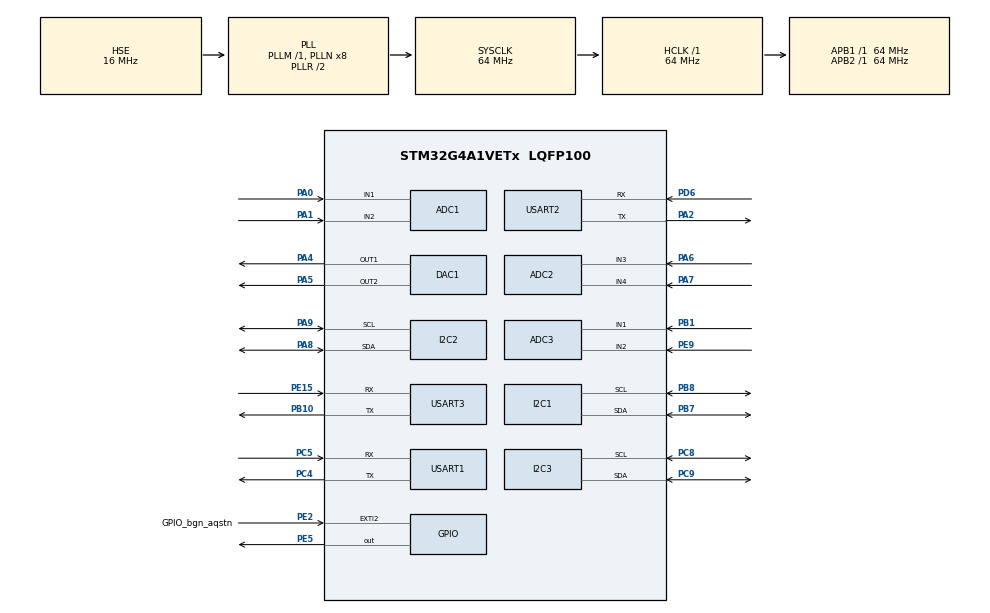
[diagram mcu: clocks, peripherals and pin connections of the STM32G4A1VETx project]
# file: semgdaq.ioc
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ADC1.Channel-0\#ChannelRegularConversion=ADC_CHANNEL_1
ADC1.Channel-1\#ChannelRegularConversion=ADC_CHANNEL_2
ADC1.ContinuousConvMode=DISABLE
ADC1.DMAContinuousRequests=ENABLE
ADC1.ExternalTrigConv=ADC_EXTERNALTRIG_T6_TRGO
ADC1.NbrOfConversion=2
ADC1.NbrOfConversionFlag=1
ADC1.OffsetNumber-0\#ChannelRegularConversion=ADC_OFFSET_NONE
ADC1.OffsetNumber-1\#ChannelRegularConversion=ADC_OFFSET_NONE
ADC1.Rank-0\#ChannelRegularConversion=1
ADC1.Rank-1\#ChannelRegularConversion=2
ADC1.SamplingTime-0\#ChannelRegularConversion=ADC_SAMPLETIME_92CYCLES_5
ADC1.SamplingTime-1\#ChannelRegularConversion=ADC_SAMPLETIME_92CYCLES_5
ADC1.master=1
ADC2.Channel-0\#ChannelRegularConversion=ADC_CHANNEL_3
ADC2.Channel-1\#ChannelRegularConversion=ADC_CHANNEL_4
ADC2.DMAContinuousRequests=ENABLE
ADC2.ExternalTrigConv=ADC_EXTERNALTRIG_T7_TRGO
ADC2.NbrOfConversion=2
ADC2.NbrOfConversionFlag=1
ADC2.OffsetNumber-0\#ChannelRegularConversion=ADC_OFFSET_NONE
ADC2.OffsetNumber-1\#ChannelRegularConversion=ADC_OFFSET_NONE
ADC2.Rank-0\#ChannelRegularConversion=1
ADC2.Rank-1\#ChannelRegularConversion=2
ADC2.SamplingTime-0\#ChannelRegularConversion=ADC_SAMPLETIME_92CYCLES_5
ADC2.SamplingTime-1\#ChannelRegularConversion=ADC_SAMPLETIME_92CYCLES_5
ADC3.Channel-0\#ChannelRegularConversion=ADC_CHANNEL_1
ADC3.Channel-1\#ChannelRegularConversion=ADC_CHANNEL_2
ADC3.DMAContinuousRequests=ENABLE
ADC3.ExternalTrigConv=ADC_EXTERNALTRIG_T20_TRGO
ADC3.NbrOfConversion=2
ADC3.NbrOfConversionFlag=1
ADC3.OffsetNumber-0\#ChannelRegularConversion=ADC_OFFSET_NONE
ADC3.OffsetNumber-1\#ChannelRegularConversion=ADC_OFFSET_NONE
ADC3.Rank-0\#ChannelRegularConversion=1
ADC3.Rank-1\#ChannelRegularConversion=2
ADC3.SamplingTime-0\#ChannelRegularConversion=ADC_SAMPLETIME_92CYCLES_5
ADC3.SamplingTime-1\#ChannelRegularConversion=ADC_SAMPLETIME_92CYCLES_5
ADC3.master=1
DAC1.DAC_Channel-DAC_OUT2=DAC_CHANNEL_2
DAC1.DAC_Trigger_OUT1-DAC_OUT1=DAC_TRIGGER_T6_TRGO
DAC1.DAC_Trigger_OUT2-DAC_OUT2=DAC_TRIGGER_T7_TRGO
Dma.ADC1.0.Direction=DMA_PERIPH_TO_MEMORY
Dma.ADC1.0.EventEnable=DISABLE
Dma.ADC1.0.Instance=DMA1_Channel1
Dma.ADC1.0.MemDataAlignment=DMA_MDATAALIGN_WORD
Dma.ADC1.0.MemInc=DMA_MINC_ENABLE
Dma.ADC1.0.Mode=DMA_CIRCULAR
Dma.ADC1.0.PeriphDataAlignment=DMA_PDATAALIGN_HALFWORD
Dma.ADC1.0.PeriphInc=DMA_PINC_DISABLE
Dma.ADC1.0.Polarity=HAL_DMAMUX_REQ_GEN_RISING
Dma.ADC1.0.Priority=DMA_PRIORITY_LOW
Dma.ADC1.0.RequestNumber=1
Dma.ADC1.0.SignalID=NONE
Dma.ADC1.0.SyncEnable=DISABLE
Dma.ADC1.0.SyncPolarity=HAL_DMAMUX_SYNC_NO_EVENT
Dma.ADC1.0.SyncRequestNumber=1
Dma.ADC1.0.SyncSignalID=NONE
Dma.ADC2.1.Direction=DMA_PERIPH_TO_MEMORY
Dma.ADC2.1.EventEnable=DISABLE
Dma.ADC2.1.Instance=DMA1_Channel6
Dma.ADC2.1.MemDataAlignment=DMA_MDATAALIGN_WORD
Dma.ADC2.1.MemInc=DMA_MINC_ENABLE
Dma.ADC2.1.Mode=DMA_CIRCULAR
Dma.ADC2.1.PeriphDataAlignment=DMA_PDATAALIGN_HALFWORD
Dma.ADC2.1.PeriphInc=DMA_PINC_DISABLE
Dma.ADC2.1.Polarity=HAL_DMAMUX_REQ_GEN_RISING
Dma.ADC2.1.Priority=DMA_PRIORITY_LOW
Dma.ADC2.1.RequestNumber=1
Dma.ADC2.1.SignalID=NONE
Dma.ADC2.1.SyncEnable=DISABLE
Dma.ADC2.1.SyncPolarity=HAL_DMAMUX_SYNC_NO_EVENT
Dma.ADC2.1.SyncRequestNumber=1
Dma.ADC2.1.SyncSignalID=NONE
Dma.ADC3.2.Direction=DMA_PERIPH_TO_MEMORY
Dma.ADC3.2.EventEnable=DISABLE
Dma.ADC3.2.Instance=DMA2_Channel1
Dma.ADC3.2.MemDataAlignment=DMA_MDATAALIGN_WORD
Dma.ADC3.2.MemInc=DMA_MINC_ENABLE
Dma.ADC3.2.Mode=DMA_CIRCULAR
Dma.ADC3.2.PeriphDataAlignment=DMA_PDATAALIGN_HALFWORD
Dma.ADC3.2.PeriphInc=DMA_PINC_DISABLE
Dma.ADC3.2.Polarity=HAL_DMAMUX_REQ_GEN_RISING
Dma.ADC3.2.Priority=DMA_PRIORITY_LOW
Dma.ADC3.2.RequestNumber=1
Dma.ADC3.2.SignalID=NONE
Dma.ADC3.2.SyncEnable=DISABLE
Dma.ADC3.2.SyncPolarity=HAL_DMAMUX_SYNC_NO_EVENT
Dma.ADC3.2.SyncRequestNumber=1
Dma.ADC3.2.SyncSignalID=NONE
Dma.DAC1_CH1.3.Direction=DMA_MEMORY_TO_PERIPH
Dma.DAC1_CH1.3.EventEnable=DISABLE
Dma.DAC1_CH1.3.Instance=DMA1_Channel3
Dma.DAC1_CH1.3.MemDataAlignment=DMA_MDATAALIGN_WORD
Dma.DAC1_CH1.3.MemInc=DMA_MINC_ENABLE
Dma.DAC1_CH1.3.Mode=DMA_CIRCULAR
Dma.DAC1_CH1.3.PeriphDataAlignment=DMA_PDATAALIGN_WORD
Dma.DAC1_CH1.3.PeriphInc=DMA_PINC_DISABLE
Dma.DAC1_CH1.3.Polarity=HAL_DMAMUX_REQ_GEN_RISING
Dma.DAC1_CH1.3.Priority=DMA_PRIORITY_LOW
Dma.DAC1_CH1.3.RequestNumber=1
Dma.DAC1_CH1.3.SignalID=NONE
Dma.DAC1_CH1.3.SyncEnable=DISABLE
Dma.DAC1_CH1.3.SyncPolarity=HAL_DMAMUX_SYNC_NO_EVENT
Dma.DAC1_CH1.3.SyncRequestNumber=1
Dma.DAC1_CH1.3.SyncSignalID=NONE
Dma.DAC1_CH2.4.Direction=DMA_MEMORY_TO_PERIPH
Dma.DAC1_CH2.4.EventEnable=DISABLE
Dma.DAC1_CH2.4.Instance=DMA2_Channel6
Dma.DAC1_CH2.4.MemDataAlignment=DMA_MDATAALIGN_WORD
Dma.DAC1_CH2.4.MemInc=DMA_MINC_ENABLE
Dma.DAC1_CH2.4.Mode=DMA_CIRCULAR
Dma.DAC1_CH2.4.PeriphDataAlignment=DMA_PDATAALIGN_WORD
Dma.DAC1_CH2.4.PeriphInc=DMA_PINC_DISABLE
Dma.DAC1_CH2.4.Polarity=HAL_DMAMUX_REQ_GEN_RISING
Dma.DAC1_CH2.4.Priority=DMA_PRIORITY_LOW
Dma.DAC1_CH2.4.RequestNumber=1
Dma.DAC1_CH2.4.SignalID=NONE
Dma.DAC1_CH2.4.SyncEnable=DISABLE
Dma.DAC1_CH2.4.SyncPolarity=HAL_DMAMUX_SYNC_NO_EVENT
Dma.DAC1_CH2.4.SyncRequestNumber=1
Dma.DAC1_CH2.4.SyncSignalID=NONE
Dma.I2C1_TX.8.Direction=DMA_MEMORY_TO_PERIPH
Dma.I2C1_TX.8.EventEnable=DISABLE
Dma.I2C1_TX.8.Instance=DMA1_Channel4
Dma.I2C1_TX.8.MemDataAlignment=DMA_MDATAALIGN_WORD
Dma.I2C1_TX.8.MemInc=DMA_MINC_ENABLE
Dma.I2C1_TX.8.Mode=DMA_CIRCULAR
Dma.I2C1_TX.8.PeriphDataAlignment=DMA_PDATAALIGN_WORD
Dma.I2C1_TX.8.PeriphInc=DMA_PINC_DISABLE
Dma.I2C1_TX.8.Polarity=HAL_DMAMUX_REQ_GEN_RISING
Dma.I2C1_TX.8.Priority=DMA_PRIORITY_LOW
Dma.I2C1_TX.8.RequestNumber=1
Dma.I2C1_TX.8.SignalID=NONE
Dma.I2C1_TX.8.SyncEnable=DISABLE
Dma.I2C1_TX.8.SyncPolarity=HAL_DMAMUX_SYNC_NO_EVENT
Dma.I2C1_TX.8.SyncRequestNumber=1
Dma.I2C1_TX.8.SyncSignalID=NONE
Dma.I2C2_TX.9.Direction=DMA_MEMORY_TO_PERIPH
Dma.I2C2_TX.9.EventEnable=DISABLE
Dma.I2C2_TX.9.Instance=DMA2_Channel5
Dma.I2C2_TX.9.MemDataAlignment=DMA_MDATAALIGN_WORD
Dma.I2C2_TX.9.MemInc=DMA_MINC_ENABLE
Dma.I2C2_TX.9.Mode=DMA_CIRCULAR
Dma.I2C2_TX.9.PeriphDataAlignment=DMA_PDATAALIGN_WORD
Dma.I2C2_TX.9.PeriphInc=DMA_PINC_DISABLE
Dma.I2C2_TX.9.Polarity=HAL_DMAMUX_REQ_GEN_RISING
Dma.I2C2_TX.9.Priority=DMA_PRIORITY_LOW
Dma.I2C2_TX.9.RequestNumber=1
Dma.I2C2_TX.9.SignalID=NONE
Dma.I2C2_TX.9.SyncEnable=DISABLE
Dma.I2C2_TX.9.SyncPolarity=HAL_DMAMUX_SYNC_NO_EVENT
Dma.I2C2_TX.9.SyncRequestNumber=1
Dma.I2C2_TX.9.SyncSignalID=NONE
Dma.I2C3_TX.10.Direction=DMA_MEMORY_TO_PERIPH
Dma.I2C3_TX.10.EventEnable=DISABLE
Dma.I2C3_TX.10.Instance=DMA2_Channel7
Dma.I2C3_TX.10.MemDataAlignment=DMA_MDATAALIGN_WORD
Dma.I2C3_TX.10.MemInc=DMA_MINC_ENABLE
Dma.I2C3_TX.10.Mode=DMA_CIRCULAR
Dma.I2C3_TX.10.PeriphDataAlignment=DMA_PDATAALIGN_WORD
Dma.I2C3_TX.10.PeriphInc=DMA_PINC_DISABLE
Dma.I2C3_TX.10.Polarity=HAL_DMAMUX_REQ_GEN_RISING
Dma.I2C3_TX.10.Priority=DMA_PRIORITY_LOW
Dma.I2C3_TX.10.RequestNumber=1
Dma.I2C3_TX.10.SignalID=NONE
Dma.I2C3_TX.10.SyncEnable=DISABLE
Dma.I2C3_TX.10.SyncPolarity=HAL_DMAMUX_SYNC_NO_EVENT
Dma.I2C3_TX.10.SyncRequestNumber=1
Dma.I2C3_TX.10.SyncSignalID=NONE
Dma.Request0=ADC1
Dma.Request1=ADC2
Dma.Request10=I2C3_TX
Dma.Request2=ADC3
Dma.Request3=DAC1_CH1
Dma.Request4=DAC1_CH2
Dma.Request5=USART1_TX
Dma.Request6=USART3_TX
Dma.Request7=USART2_TX
Dma.Request8=I2C1_TX
Dma.Request9=I2C2_TX
Dma.USART1_TX.5.Direction=DMA_MEMORY_TO_PERIPH
Dma.USART1_TX.5.EventEnable=DISABLE
Dma.USART1_TX.5.Instance=DMA1_Channel2
Dma.USART1_TX.5.MemDataAlignment=DMA_MDATAALIGN_WORD
Dma.USART1_TX.5.MemInc=DMA_MINC_ENABLE
Dma.USART1_TX.5.Mode=DMA_CIRCULAR
Dma.USART1_TX.5.PeriphDataAlignment=DMA_PDATAALIGN_WORD
Dma.USART1_TX.5.PeriphInc=DMA_PINC_DISABLE
Dma.USART1_TX.5.Polarity=HAL_DMAMUX_REQ_GEN_RISING
Dma.USART1_TX.5.Priority=DMA_PRIORITY_LOW
Dma.USART1_TX.5.RequestNumber=1
Dma.USART1_TX.5.SignalID=NONE
Dma.USART1_TX.5.SyncEnable=DISABLE
Dma.USART1_TX.5.SyncPolarity=HAL_DMAMUX_SYNC_NO_EVENT
Dma.USART1_TX.5.SyncRequestNumber=1
Dma.USART1_TX.5.SyncSignalID=NONE
Dma.USART2_TX.7.Direction=DMA_MEMORY_TO_PERIPH
Dma.USART2_TX.7.EventEnable=DISABLE
Dma.USART2_TX.7.Instance=DMA1_Channel5
Dma.USART2_TX.7.MemDataAlignment=DMA_MDATAALIGN_WORD
Dma.USART2_TX.7.MemInc=DMA_MINC_ENABLE
Dma.USART2_TX.7.Mode=DMA_CIRCULAR
Dma.USART2_TX.7.PeriphDataAlignment=DMA_PDATAALIGN_WORD
Dma.USART2_TX.7.PeriphInc=DMA_PINC_DISABLE
Dma.USART2_TX.7.Polarity=HAL_DMAMUX_REQ_GEN_RISING
Dma.USART2_TX.7.Priority=DMA_PRIORITY_LOW
Dma.USART2_TX.7.RequestNumber=1
Dma.USART2_TX.7.SignalID=NONE
Dma.USART2_TX.7.SyncEnable=DISABLE
Dma.USART2_TX.7.SyncPolarity=HAL_DMAMUX_SYNC_NO_EVENT
Dma.USART2_TX.7.SyncRequestNumber=1
Dma.USART2_TX.7.SyncSignalID=NONE
Dma.USART3_TX.6.Direction=DMA_MEMORY_TO_PERIPH
Dma.USART3_TX.6.EventEnable=DISABLE
Dma.USART3_TX.6.Instance=DMA2_Channel4
Dma.USART3_TX.6.MemDataAlignment=DMA_MDATAALIGN_WORD
Dma.USART3_TX.6.MemInc=DMA_MINC_ENABLE
Dma.USART3_TX.6.Mode=DMA_CIRCULAR
Dma.USART3_TX.6.PeriphDataAlignment=DMA_PDATAALIGN_WORD
Dma.USART3_TX.6.PeriphInc=DMA_PINC_DISABLE
Dma.USART3_TX.6.Polarity=HAL_DMAMUX_REQ_GEN_RISING
Dma.USART3_TX.6.Priority=DMA_PRIORITY_LOW
Dma.USART3_TX.6.RequestNumber=1
Dma.USART3_TX.6.SignalID=NONE
Dma.USART3_TX.6.SyncEnable=DISABLE
Dma.USART3_TX.6.SyncPolarity=HAL_DMAMUX_SYNC_NO_EVENT
Dma.USART3_TX.6.SyncRequestNumber=1
Dma.USART3_TX.6.SyncSignalID=NONE
I2C1.Timing=0x10707DBC
I2C2.Timing=0x10707DBC
I2C3.Timing=0x10707DBC
Mcu.Family=STM32G4
Mcu.Name=STM32G4A1VETx
Mcu.Package=LQFP100
NVIC.DMA1_Channel1_IRQn=true\:0\:0\:false\:false\:true\:false\:true\:true
NVIC.DMA1_Channel2_IRQn=true\:0\:0\:false\:false\:true\:false\:true\:true
NVIC.DMA1_Channel3_IRQn=true\:0\:0\:false\:false\:true\:false\:true\:true
NVIC.DMA1_Channel4_IRQn=true\:0\:0\:false\:false\:true\:false\:true\:true
NVIC.DMA1_Channel5_IRQn=true\:0\:0\:false\:false\:true\:false\:true\:true
NVIC.DMA1_Channel6_IRQn=true\:0\:0\:false\:false\:true\:false\:true\:true
NVIC.DMA2_Channel1_IRQn=true\:0\:0\:false\:false\:true\:false\:true\:true
NVIC.DMA2_Channel4_IRQn=true\:0\:0\:false\:false\:true\:false\:true\:true
NVIC.DMA2_Channel5_IRQn=true\:0\:0\:false\:false\:true\:false\:true\:true
NVIC.DMA2_Channel6_IRQn=true\:0\:0\:false\:false\:true\:false\:true\:true
NVIC.DMA2_Channel7_IRQn=true\:0\:0\:false\:false\:true\:false\:true\:true
NVIC.PriorityGroup=NVIC_PRIORITYGROUP_4
PA0.Mode=IN1-Single-Ended
PA0.Signal=ADC1_IN1
PA1.Mode=IN2-Single-Ended
PA1.Signal=ADC1_IN2
PA13.Mode=JTAG_4_pins
PA13.Signal=SYS_JTMS-SWDIO
PA14.Mode=JTAG_4_pins
PA14.Signal=SYS_JTCK-SWCLK
PA15.Mode=JTAG_4_pins
PA15.Signal=SYS_JTDI
PA2.Mode=Asynchronous
PA2.Signal=USART2_TX
PA4.Signal=COMP_DAC11_group
PA5.Signal=COMP_DAC12_group
PA6.Mode=IN3-Single-Ended
PA6.Signal=ADC2_IN3
PA7.Mode=IN4-Single-Ended
PA7.Signal=ADC2_IN4
PA8.Mode=I2C
PA8.Signal=I2C2_SDA
PA9.Mode=I2C
PA9.Signal=I2C2_SCL
PB1.Mode=IN1-Single-Ended
PB1.Signal=ADC3_IN1
PB10.Mode=Asynchronous
PB10.Signal=USART3_TX
PB3.Mode=JTAG_4_pins
PB3.Signal=SYS_JTDO-SWO
PB7.Mode=I2C
PB7.Signal=I2C1_SDA
PB8-BOOT0.Mode=I2C
PB8-BOOT0.Signal=I2C1_SCL
PC4.Mode=Asynchronous
PC4.Signal=USART1_TX
PC5.Mode=Asynchronous
PC5.Signal=USART1_RX
PC8.Mode=I2C
PC8.Signal=I2C3_SCL
PC9.Mode=I2C
PC9.Signal=I2C3_SDA
PD6.Mode=Asynchronous
PD6.Signal=USART2_RX
PE15.Mode=Asynchronous
PE15.Signal=USART3_RX
PE2.GPIO_Label=GPIO_bgn_aqstn
PE2.GPIO_ModeDefaultEXTI=GPIO_MODE_IT_RISING
PE2.GPIO_PuPd=GPIO_PULLDOWN
PE2.Signal=GPXTI2
PE5.Signal=GPIO_Output
PE9.Mode=IN2-Single-Ended
PE9.Signal=ADC3_IN2
PF0-OSC_IN.Mode=HSE-External-Oscillator
PF0-OSC_IN.Signal=RCC_OSC_IN
PF1-OSC_OUT.Mode=HSE-External-Oscillator
PF1-OSC_OUT.Signal=RCC_OSC_OUT
ProjectManager.HeapSize=0x200
ProjectManager.StackSize=0x400
ProjectManager.TargetToolchain=STM32CubeIDE
RCC.ADC12Freq_Value=64000000
RCC.ADC345Freq_Value=64000000
RCC.AHBFreq_Value=64000000
RCC.APB1Freq_Value=64000000
RCC.APB1TimFreq_Value=64000000
RCC.APB2Freq_Value=64000000
RCC.APB2TimFreq_Value=64000000
RCC.CortexFreq_Value=64000000
RCC.EXTERNAL_CLOCK_VALUE=12288000
RCC.HCLKFreq_Value=64000000
RCC.HSE_VALUE=16000000
RCC.HSI48_VALUE=48000000
RCC.HSI_VALUE=16000000
RCC.LSE_VALUE=32768
RCC.PLLSourceVirtual=RCC_PLLSOURCE_HSE
RCC.SYSCLKFreq_VALUE=64000000
RCC.SYSCLKSource=RCC_SYSCLKSOURCE_PLLCLK
RCC.USBFreq_Value=48000000
RCC.VCOOutputFreq_Value=128000000
SH.COMP_DAC11_group.0=DAC1_OUT1,DAC_OUT1
SH.COMP_DAC12_group.0=DAC1_OUT2,DAC_OUT2
TIM20.PeriodNoDither=8-1
TIM20.Prescaler=8-1
TIM20.TIM_MasterOutputTrigger=TIM_TRGO_UPDATE
TIM6.PeriodNoDither=8-1
TIM6.Prescaler=8-1
TIM6.TIM_MasterOutputTrigger=TIM_TRGO_UPDATE
TIM7.PeriodNoDither=8-1
TIM7.Prescaler=8-1
TIM7.TIM_MasterOutputTrigger=TIM_TRGO_UPDATE
USART1.VirtualMode-Asynchronous=VM_ASYNC
USART2.VirtualMode-Asynchronous=VM_ASYNC
USART3.VirtualMode-Asynchronous=VM_ASYNC
VP_FMAC_VS_FMAC.Mode=FMAC_Activate
VP_SYS_VS_DBSignals.Mode=DisableDeadBatterySignals
VP_TIM20_VS_ClockSourceITR.Mode=TriggerSource_ITR0
VP_TIM6_VS_ClockSourceINT.Mode=Enable_Timer
VP_TIM7_VS_ClockSourceINT.Mode=Enable_Timer
board=custom

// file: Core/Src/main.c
/* USER CODE BEGIN Header */
/**
  ******************************************************************************
  * @file           : main.c
  * @brief          : Main program body
  ******************************************************************************
  * @attention
  *
  * Copyright (c) 2024 STMicroelectronics.
  * All rights reserved.
  *
  * This software is licensed under terms that can be found in the LICENSE file
  * in the root directory of this software component.
  * If no LICENSE file comes with this software, it is provided AS-IS.
  *
  ******************************************************************************
  */
/* USER CODE END Header */
#include "main.h"

/* USER CODE BEGIN Includes */
#include <_ADCn_INx_DAC1_Cond.h>
/* USER CODE END Includes */

/* USER CODE BEGIN PD */
#define NOOFITERATIONS_BL 20
/* USER CODE END PD */

ADC_HandleTypeDef hadc1;
ADC_HandleTypeDef hadc2;
ADC_HandleTypeDef hadc3;
DMA_HandleTypeDef hdma_adc1;
DMA_HandleTypeDef hdma_adc2;
DMA_HandleTypeDef hdma_adc3;

DAC_HandleTypeDef hdac1;
DMA_HandleTypeDef hdma_dac1_ch1;
DMA_HandleTypeDef hdma_dac1_ch2;

FMAC_HandleTypeDef hfmac;

I2C_HandleTypeDef hi2c1;
I2C_HandleTypeDef hi2c2;
I2C_HandleTypeDef hi2c3;
DMA_HandleTypeDef hdma_i2c1_tx;
DMA_HandleTypeDef hdma_i2c2_tx;
DMA_HandleTypeDef hdma_i2c3_tx;

TIM_HandleTypeDef htim6;
TIM_HandleTypeDef htim7;
TIM_HandleTypeDef htim20;

UART_HandleTypeDef huart1;
UART_HandleTypeDef huart2;
UART_HandleTypeDef huart3;
DMA_HandleTypeDef hdma_usart1_tx;
DMA_HandleTypeDef hdma_usart2_tx;
DMA_HandleTypeDef hdma_usart3_tx;

/* USER CODE BEGIN PV */
ADC1_DMA_sort*ADC1_DMA_sort_ptr; // Declaring a pointer to the sorting structure at runtime
ADC2_DMA_sort*ADC2_DMA_sort_ptr;
ADC3_DMA_sort*ADC3_DMA_sort_ptr;

ADC1_IN1_MA MovingAverage_ADC1_IN1; // Declaring an instance of the moving average structure
ADC1_IN2_MA MovingAverage_ADC1_IN2;
ADC2_IN3_MA MovingAverage_ADC2_IN3;
ADC2_IN4_MA MovingAverage_ADC2_IN4;
ADC3_IN1_MA MovingAverage_ADC3_IN1;
ADC3_IN2_MA MovingAverage_ADC3_IN2;

ADC1_IN1_MA OffsetCalc_ADC1_IN1; // Declaring an instance of the Offset calculation
ADC1_IN2_MA OffsetCalc_ADC1_IN2;
ADC2_IN3_MA OffsetCalc_ADC2_IN3;
ADC2_IN4_MA OffsetCalc_ADC2_IN4;
ADC3_IN1_MA OffsetCalc_ADC3_IN1;
ADC3_IN2_MA OffsetCalc_ADC3_IN2;

ADC1_IN1_MA SD_BL_ADC1_IN1; // Declaring an instance of standard deviation calculation
ADC1_IN2_MA SD_BL_ADC1_IN2;
ADC2_IN3_MA SD_BL_ADC2_IN3;
ADC2_IN4_MA SD_BL_ADC2_IN4;
ADC3_IN1_MA SD_BL_ADC3_IN1;
ADC3_IN2_MA SD_BL_ADC3_IN2;

ADC1_IN1_MA TKEO_ADC1_IN1; // Declaring an instance of TKEO windowing
ADC1_IN2_MA TKEO_ADC1_IN2;
ADC2_IN3_MA TKEO_ADC2_IN3;
ADC2_IN4_MA TKEO_ADC2_IN4;
ADC3_IN1_MA TKEO_ADC3_IN1;
ADC3_IN2_MA TKEO_ADC3_IN2;

ADC1_IN1_MA SSC_ADC1_IN1; // Declaring an instance of slope sign change feature
ADC1_IN2_MA SSC_ADC1_IN2;
ADC2_IN3_MA SSC_ADC2_IN3;
ADC2_IN4_MA SSC_ADC2_IN4;
ADC3_IN1_MA SSC_ADC3_IN1;
ADC3_IN2_MA SSC_ADC3_IN2;

ADC1_IN1_MA STFT_ADC1_IN1; // Declaring an instance of short time Fourier transform
ADC1_IN2_MA STFT_ADC1_IN2;
ADC2_IN3_MA STFT_ADC2_IN3;
ADC2_IN4_MA STFT_ADC2_IN4;
ADC3_IN1_MA STFT_ADC3_IN1;
ADC3_IN2_MA STFT_ADC3_IN2;

ADC1_IN1_MA DAC1_ADC1_IN1; // Declaring an instance for DAC monitoring
ADC1_IN2_MA DAC1_ADC1_IN2;
ADC2_IN3_MA DAC1_ADC2_IN3;
ADC2_IN4_MA DAC1_ADC2_IN4;
ADC3_IN1_MA DAC1_ADC3_IN1;
ADC3_IN2_MA DAC1_ADC3_IN2;

ADC1_IN1_STFT_par STFT_par_ADC1_IN1; // Declaring an instance of short time Fourier transform parameters
ADC1_IN2_STFT_par STFT_par_ADC1_IN2;
ADC2_IN3_STFT_par STFT_par_ADC2_IN3;
ADC2_IN4_STFT_par STFT_par_ADC2_IN4;
ADC3_IN1_STFT_par STFT_par_ADC3_IN1;
ADC3_IN2_STFT_par STFT_par_ADC3_IN2;

HAL_StatusTypeDef ADC_status;

float32_t Offset_1 = 0.0f; // Variable to store the calculated offset
float32_t Offset_2 = 0.0f;
float32_t Offset_3 = 0.0f;
float32_t Offset_4 = 0.0f;
float32_t Offset_5 = 0.0f;
float32_t Offset_6 = 0.0f;

uint8_t Offset_1_Calculated = 0; // Initialize the offset calculation flag to zero
uint8_t Offset_2_Calculated = 0;
uint8_t Offset_3_Calculated = 0;
uint8_t Offset_4_Calculated = 0;
uint8_t Offset_5_Calculated = 0;
uint8_t Offset_6_Calculated = 0;

float32_t SD_BL_1 = 0.0f;
float32_t SD_BL_2 = 0.0f;
float32_t SD_BL_3 = 0.0f;
float32_t SD_BL_4 = 0.0f;
float32_t SD_BL_5 = 0.0f;
float32_t SD_BL_6 = 0.0f;

uint8_t TKEO_1 = 0;
uint8_t TKEO_2 = 0;
uint8_t TKEO_3 = 0;
uint8_t TKEO_4 = 0;
uint8_t TKEO_5 = 0;
uint8_t TKEO_6 = 0;

float32_t SSC_1 = 0.0f;
float32_t SSC_2 = 0.0f;
float32_t SSC_3 = 0.0f;
float32_t SSC_4 = 0.0f;
float32_t SSC_5 = 0.0f;
float32_t SSC_6 = 0.0f;

float32_t* AR_1;
float32_t* AR_2;
float32_t* AR_3;
float32_t* AR_4;
float32_t* AR_5;
float32_t* AR_6;

float32_t* STFT_1;
float32_t* STFT_2;
float32_t* STFT_3;
float32_t* STFT_4;
float32_t* STFT_5;
float32_t* STFT_6;

volatile uint8_t Buffer_ADC1_Ready = 0;
volatile uint8_t Buffer_ADC2_Ready = 0;
volatile uint8_t Buffer_ADC3_Ready = 0;
/* USER CODE END PV */

void SystemClock_Config(void);
static void MX_GPIO_Init(void);
static void MX_DMA_Init(void);
static void MX_ADC1_Init(void);
static void MX_ADC2_Init(void);
static void MX_ADC3_Init(void);
static void MX_FMAC_Init(void);
static void MX_TIM6_Init(void);
static void MX_TIM7_Init(void);
static void MX_TIM20_Init(void);
static void MX_DAC1_Init(void);
static void MX_USART1_UART_Init(void);
static void MX_USART3_UART_Init(void);
static void MX_USART2_UART_Init(void);
static void MX_I2C1_Init(void);
static void MX_I2C2_Init(void);
static void MX_I2C3_Init(void);
/* USER CODE BEGIN PFP */
void EXT12_IRQHandler(void);
void HAL_GPIO_EXTI_Callback(uint16_t GPIO_Pin);
void                    HAL_ADC_ConvHalfCpltCallback(ADC_HandleTypeDef *hadc);
void                    HAL_ADC_ConvCpltCallback(ADC_HandleTypeDef *hadc);
void Error_Handler(void);
/* USER CODE END PFP */

int main(void)
{

  /* MCU Configuration--------------------------------------------------------*/

  /* Reset of all peripherals, Initializes the Flash interface and the Systick. */
  HAL_Init();

  /* USER CODE BEGIN Init */
  init_ADC1_IN1_struct(); // Pointer to the source buffer is initialized at runtime
  init_ADC1_IN1_FO_biquad_filter();  // Initializes the filter coefficients and variables
  MA_ADC1_IN1_Init(&MovingAverage_ADC1_IN1); // Initializes all the output and moving average buffers to zero and the index to zero

  init_ADC1_IN2_struct();
  init_ADC1_IN2_FO_biquad_filter();
  MA_ADC1_IN2_Init(&MovingAverage_ADC1_IN2);

  init_ADC2_IN3_struct();
  init_ADC2_IN3_FO_biquad_filter();
  MA_ADC2_IN3_Init(&MovingAverage_ADC2_IN3);

  init_ADC2_IN4_struct();
  init_ADC2_IN4_FO_biquad_filter();
  MA_ADC2_IN4_Init(&MovingAverage_ADC2_IN4);

  init_ADC3_IN1_struct();
  init_ADC3_IN1_FO_biquad_filter();
  MA_ADC3_IN1_Init(&MovingAverage_ADC3_IN1);

  init_ADC3_IN2_struct();
  init_ADC3_IN2_FO_biquad_filter();
  MA_ADC3_IN2_Init(&MovingAverage_ADC3_IN2);
  /* USER CODE END Init */

  /* Configure the system clock */
  SystemClock_Config();

  /* Initialize all configured peripherals */
  MX_GPIO_Init();
  MX_DMA_Init();
  MX_ADC1_Init();
  MX_ADC2_Init();
  MX_ADC3_Init();
  MX_FMAC_Init();
  MX_TIM6_Init();
  MX_TIM7_Init();
  MX_TIM20_Init();
  MX_DAC1_Init();
  MX_USART1_UART_Init();
  MX_USART3_UART_Init();
  MX_USART2_UART_Init();
  MX_I2C1_Init();
  MX_I2C2_Init();
  MX_I2C3_Init();
  /* USER CODE BEGIN 2 */
  // Enable the EXTI line 2 interrupt
  HAL_NVIC_SetPriority(EXTI2_IRQn, 2, 0);  // Set priority
  HAL_NVIC_EnableIRQ(EXTI2_IRQn); // Enable the interrupt in NVIC (Interrupt is triggered by pressing the push button)

  EXT12_IRQHandler(); // When the push button is pressed - starts all ADCs with DMA, starts the sorting algorithm for each ADC, calculates the offset from the baseline and the standard deviation from the baseline data (for all channels). Finally, it toggles the status LED to indicate that acquisition has started
  /* USER CODE END 2 */

  /* Infinite loop */
  /* USER CODE BEGIN WHILE */
  while (1)
  {
	if (Buffer_ADC1_Ready == 1) // Checks if the flag for the channel buffer fills is set for ADC1
	{
	  /* DSP SECTION */
	  update_ADC1_IN1_FO_biquad_filter();  // Filters channel 1 data
	  MA_ADC1_IN1_Update(&MovingAverage_ADC1_IN1); // Performs the moving average
	  for (uint32_t y = 0; y < ADC_DMA_SIXTEENTHBUFFERSIZE; y++)
	  {
		  MovingAverage_ADC1_IN1.MA_ADC1_IN1_OutBfr[y]  -= Offset_1; // Subtracts the stored offset
	  }
      #ifdef MONITOR_CHANNEL_1_LEFT
	  ADC1_IN1_DAC_Update(&DAC1_ADC1_IN1); // For monitoring the channel on an oscilloscope through the DAC
      #endif

	  /* FEATURE EXCTRACTION SECTION */
      TKEO_1 = ADC1_IN1_TKEO(&TKEO_ADC1_IN1, SD_BL_1); // Performs the windowing through the TKEO operator and returns binary data to indicate presence or absence of muscle activation

      if(TKEO_1 == 1) // Only runs when there is muscle activation.
      {
      /* Slope sign change */
      SSC_1 = ADC1_IN1_SSC(&SSC_ADC1_IN1, 0.5 * Offset_1); // Calculates slope sign changes for active segments
      /*Computes the autocorrelation values and the autoregression coefficients and returns the latter*/
      ADC1_IN1_autocorr_calc();
      AR_1 = ADC1_IN1_autoreg_coeffs();
      /* Computes the Short Time Fourier Transform from the moving average buffer */
      STFT_1 = ADC1_IN1_STFT_Update(&STFT_par_ADC1_IN1, &STFT_ADC1_IN1);
      }

	  update_ADC1_IN2_FO_biquad_filter();
	  MA_ADC1_IN2_Update(&MovingAverage_ADC1_IN2);
	  for (uint32_t z = 0; z < ADC_DMA_SIXTEENTHBUFFERSIZE; z++)
	  {
		  MovingAverage_ADC1_IN2.MA_ADC1_IN2_OutBfr[z]  -= Offset_2;
	  }
      #ifdef MONITOR_CHANNEL_4_RIGHT
	  ADC1_IN2_DAC_Update(&DAC1_ADC1_IN2);
      #endif

	  TKEO_2 = ADC1_IN2_TKEO(&TKEO_ADC1_IN2, SD_BL_2);

	  if(TKEO_2 == 1)
	  {
	  SSC_2 = ADC1_IN2_SSC(&SSC_ADC1_IN2, 0.5 * Offset_2);
	  ADC1_IN2_autocorr_calc();
	  AR_2 = ADC1_IN2_autoreg_coeffs();
	  STFT_2 = ADC1_IN2_STFT_Update(&STFT_par_ADC1_IN2, &STFT_ADC1_IN2);
	  }

	  Buffer_ADC1_Ready = 0; // After processing is done the flag is cleared

	}

	if (Buffer_ADC2_Ready == 1)
	{
	  update_ADC2_IN3_FO_biquad_filter();
	  MA_ADC2_IN3_Update(&MovingAverage_ADC2_IN3);
	  for (uint32_t g = 0; g <ADC_DMA_SIXTEENTHBUFFERSIZE; g++)
	  {
		  MovingAverage_ADC2_IN3.MA_ADC2_IN3_OutBfr[g]  -= Offset_3;
	  }

      #ifdef MONITOR_CHANNEL_2_LEFT
	  ADC2_IN3_DAC_Update(&DAC1_ADC2_IN3);
      #endif

	  TKEO_3 = ADC2_IN3_TKEO(&TKEO_ADC2_IN3, SD_BL_3);

	  if(TKEO_3 == 1)
	  {
	  SSC_3 = ADC2_IN3_SSC(&SSC_ADC2_IN3, 0.5 * Offset_3);
	  ADC2_IN3_autocorr_calc();
	  AR_3 = ADC2_IN3_autoreg_coeffs();
	  STFT_3 = ADC2_IN3_STFT_Update(&STFT_par_ADC2_IN3, &STFT_ADC2_IN3);
	  }

	  update_ADC2_IN4_FO_biquad_filter();
	  MA_ADC2_IN4_Update(&MovingAverage_ADC2_IN4);
	  for (uint32_t e = 0; e < ADC_DMA_SIXTEENTHBUFFERSIZE; e++)
	  {
		  MovingAverage_ADC2_IN4.MA_ADC2_IN4_OutBfr[e]  -= Offset_4;
	  }

      #ifdef MONITOR_CHANNEL_5_RIGHT
	  ADC2_IN4_DAC_Update(&DAC1_ADC2_IN4);
      #endif

	  TKEO_4 = ADC2_IN4_TKEO(&TKEO_ADC2_IN4, SD_BL_4);

	  if(TKEO_4 == 1)
	  {
	  SSC_4 = ADC2_IN4_SSC(&SSC_ADC2_IN4, 0.5 * Offset_4);
	  ADC2_IN4_autocorr_calc();
	  AR_4 = ADC2_IN4_autoreg_coeffs();
	  STFT_4 = ADC2_IN4_STFT_Update(&STFT_par_ADC2_IN4, &STFT_ADC2_IN4);
	  }

	  Buffer_ADC2_Ready = 0;
	}

	if (Buffer_ADC3_Ready == 1)
	{
	  update_ADC3_IN1_FO_biquad_filter();
	  MA_ADC3_IN1_Update(&MovingAverage_ADC3_IN1);
	  for (uint32_t b = 0; b < ADC_DMA_SIXTEENTHBUFFERSIZE; b++)
	  {
		  MovingAverage_ADC3_IN1.MA_ADC3_IN1_OutBfr[b]  -= Offset_5;
	  }
      #ifdef MONITOR_CHANNEL_3_LEFT
	  ADC3_IN1_DAC_Update(&DAC1_ADC3_IN1);
      #endif

	  TKEO_5 = ADC3_IN1_TKEO(&TKEO_ADC3_IN1, SD_BL_5);

	  if(TKEO_5 == 1)
	  {
	  SSC_5 = ADC3_IN1_SSC(&SSC_ADC3_IN1, 0.5 * Offset_5);
	  ADC3_IN1_autocorr_calc();
	  AR_5 = ADC3_IN1_autoreg_coeffs();
	  STFT_5 = ADC3_IN1_STFT_Update(&STFT_par_ADC3_IN1, &STFT_ADC3_IN1);
	  }

	  /* DSP SECTION */
	  update_ADC3_IN2_FO_biquad_filter(); // Notch filters channel 2 data
	  MA_ADC3_IN2_Update(&MovingAverage_ADC3_IN2); // Performs the moving average
	  for (uint32_t c = 0; c < ADC_DMA_SIXTEENTHBUFFERSIZE; c++)
	  {
		  MovingAverage_ADC3_IN2.MA_ADC3_IN2_OutBfr[c]  -= Offset_6;  // Subtracts the stored offset
	  }
      #ifdef MONITOR_CHANNEL_6_RIGHT
	  ADC3_IN2_DAC_Update(&DAC1_ADC3_IN2); // For monitoring the channel on an oscilloscope through the DAC
      #endif

	  /* FEATURE EXCTRACTION SECTION */
	  TKEO_6 = ADC3_IN2_TKEO(&TKEO_ADC3_IN2, SD_BL_6); // Performs the windowing through the TKEO operator and returns binary data to indicate presence or absence of muscle activation

	  if(TKEO_6 == 1) // Only runs when there is muscle activation.
	  {
	  /* Slope sign change */
	  SSC_6 = ADC3_IN2_SSC(&SSC_ADC3_IN2, 0.5 * Offset_6); // Calculates slope sign changes for active segments
	  /* Computes the autocorrelation values and the autoregression coefficients and returns the latter */
	  ADC3_IN2_autocorr_calc();
	  AR_6 = ADC3_IN2_autoreg_coeffs();
	  /* Computes the Short Time Fourier Transform from the moving average buffer */
	  STFT_6 = ADC3_IN2_STFT_Update(&STFT_par_ADC3_IN2, &STFT_ADC3_IN2);
	  }

	  Buffer_ADC3_Ready = 0;
	}
    /* USER CODE END WHILE */

  }
}

void SystemClock_Config(void)
{
  RCC_OscInitTypeDef RCC_OscInitStruct = {0};
  RCC_ClkInitTypeDef RCC_ClkInitStruct = {0};

  /** Configure the main internal regulator output voltage
  */
  HAL_PWREx_ControlVoltageScaling(PWR_REGULATOR_VOLTAGE_SCALE1);

  /** Initializes the RCC Oscillators according to the specified parameters
  * in the RCC_OscInitTypeDef structure.
  */
  RCC_OscInitStruct.OscillatorType = RCC_OSCILLATORTYPE_HSE;
  RCC_OscInitStruct.HSEState = RCC_HSE_ON;
  RCC_OscInitStruct.PLL.PLLState = RCC_PLL_ON;
  RCC_OscInitStruct.PLL.PLLSource = RCC_PLLSOURCE_HSE;
  RCC_OscInitStruct.PLL.PLLM = RCC_PLLM_DIV1;
  RCC_OscInitStruct.PLL.PLLN = 8;
  RCC_OscInitStruct.PLL.PLLP = RCC_PLLP_DIV2;
  RCC_OscInitStruct.PLL.PLLQ = RCC_PLLQ_DIV2;
  RCC_OscInitStruct.PLL.PLLR = RCC_PLLR_DIV2;
  if (HAL_RCC_OscConfig(&RCC_OscInitStruct) != HAL_OK)
  {
    Error_Handler();
  }

  /** Initializes the CPU, AHB and APB buses clocks
  */
  RCC_ClkInitStruct.ClockType = RCC_CLOCKTYPE_HCLK|RCC_CLOCKTYPE_SYSCLK
                              |RCC_CLOCKTYPE_PCLK1|RCC_CLOCKTYPE_PCLK2;
  RCC_ClkInitStruct.SYSCLKSource = RCC_SYSCLKSOURCE_PLLCLK;
  RCC_ClkInitStruct.AHBCLKDivider = RCC_SYSCLK_DIV1;
  RCC_ClkInitStruct.APB1CLKDivider = RCC_HCLK_DIV1;
  RCC_ClkInitStruct.APB2CLKDivider = RCC_HCLK_DIV1;

  if (HAL_RCC_ClockConfig(&RCC_ClkInitStruct, FLASH_LATENCY_2) != HAL_OK)
  {
    Error_Handler();
  }
}

static void MX_ADC1_Init(void)
{

  ADC_MultiModeTypeDef multimode = {0};
  ADC_ChannelConfTypeDef sConfig = {0};

  /** Common config
  */
  hadc1.Instance = ADC1;
  hadc1.Init.ClockPrescaler = ADC_CLOCK_SYNC_PCLK_DIV2;
  hadc1.Init.Resolution = ADC_RESOLUTION_12B;
  hadc1.Init.DataAlign = ADC_DATAALIGN_RIGHT;
  hadc1.Init.GainCompensation = 0;
  hadc1.Init.ScanConvMode = ADC_SCAN_ENABLE;
  hadc1.Init.EOCSelection = ADC_EOC_SINGLE_CONV;
  hadc1.Init.LowPowerAutoWait = DISABLE;
  hadc1.Init.ContinuousConvMode = DISABLE;
  hadc1.Init.NbrOfConversion = 2;
  hadc1.Init.DiscontinuousConvMode = DISABLE;
  hadc1.Init.ExternalTrigConv = ADC_EXTERNALTRIG_T6_TRGO;
  hadc1.Init.ExternalTrigConvEdge = ADC_EXTERNALTRIGCONVEDGE_RISING;
  hadc1.Init.DMAContinuousRequests = ENABLE;
  hadc1.Init.Overrun = ADC_OVR_DATA_PRESERVED;
  hadc1.Init.OversamplingMode = DISABLE;
  if (HAL_ADC_Init(&hadc1) != HAL_OK)
  {
    Error_Handler();
  }

  /** Configure the ADC multi-mode
  */
  multimode.Mode = ADC_MODE_INDEPENDENT;
  if (HAL_ADCEx_MultiModeConfigChannel(&hadc1, &multimode) != HAL_OK)
  {
    Error_Handler();
  }

  /** Configure Regular Channel
  */
  sConfig.Channel = ADC_CHANNEL_1;
  sConfig.Rank = ADC_REGULAR_RANK_1;
  sConfig.SamplingTime = ADC_SAMPLETIME_92CYCLES_5;
  sConfig.SingleDiff = ADC_SINGLE_ENDED;
  sConfig.OffsetNumber = ADC_OFFSET_NONE;
  sConfig.Offset = 0;
  if (HAL_ADC_ConfigChannel(&hadc1, &sConfig) != HAL_OK)
  {
    Error_Handler();
  }

  /** Configure Regular Channel
  */
  sConfig.Channel = ADC_CHANNEL_2;
  sConfig.Rank = ADC_REGULAR_RANK_2;
  if (HAL_ADC_ConfigChannel(&hadc1, &sConfig) != HAL_OK)
  {
    Error_Handler();
  }

}

static void MX_ADC2_Init(void)
{

  ADC_ChannelConfTypeDef sConfig = {0};

  /** Common config
  */
  hadc2.Instance = ADC2;
  hadc2.Init.ClockPrescaler = ADC_CLOCK_SYNC_PCLK_DIV2;
  hadc2.Init.Resolution = ADC_RESOLUTION_12B;
  hadc2.Init.DataAlign = ADC_DATAALIGN_RIGHT;
  hadc2.Init.GainCompensation = 0;
  hadc2.Init.ScanConvMode = ADC_SCAN_ENABLE;
  hadc2.Init.EOCSelection = ADC_EOC_SINGLE_CONV;
  hadc2.Init.LowPowerAutoWait = DISABLE;
  hadc2.Init.ContinuousConvMode = DISABLE;
  hadc2.Init.NbrOfConversion = 2;
  hadc2.Init.DiscontinuousConvMode = DISABLE;
  hadc2.Init.ExternalTrigConv = ADC_EXTERNALTRIG_T7_TRGO;
  hadc2.Init.ExternalTrigConvEdge = ADC_EXTERNALTRIGCONVEDGE_RISING;
  hadc2.Init.DMAContinuousRequests = ENABLE;
  hadc2.Init.Overrun = ADC_OVR_DATA_PRESERVED;
  hadc2.Init.OversamplingMode = DISABLE;
  if (HAL_ADC_Init(&hadc2) != HAL_OK)
  {
    Error_Handler();
  }

  /** Configure Regular Channel
  */
  sConfig.Channel = ADC_CHANNEL_3;
  sConfig.Rank = ADC_REGULAR_RANK_1;
  sConfig.SamplingTime = ADC_SAMPLETIME_92CYCLES_5;
  sConfig.SingleDiff = ADC_SINGLE_ENDED;
  sConfig.OffsetNumber = ADC_OFFSET_NONE;
  sConfig.Offset = 0;
  if (HAL_ADC_ConfigChannel(&hadc2, &sConfig) != HAL_OK)
  {
    Error_Handler();
  }

  /** Configure Regular Channel
  */
  sConfig.Channel = ADC_CHANNEL_4;
  sConfig.Rank = ADC_REGULAR_RANK_2;
  if (HAL_ADC_ConfigChannel(&hadc2, &sConfig) != HAL_OK)
  {
    Error_Handler();
  }

}

static void MX_ADC3_Init(void)
{

  ADC_ChannelConfTypeDef sConfig = {0};

  /** Common config
  */
  hadc3.Instance = ADC3;
  hadc3.Init.ClockPrescaler = ADC_CLOCK_SYNC_PCLK_DIV2;
  hadc3.Init.Resolution = ADC_RESOLUTION_12B;
  hadc3.Init.DataAlign = ADC_DATAALIGN_RIGHT;
  hadc3.Init.GainCompensation = 0;
  hadc3.Init.ScanConvMode = ADC_SCAN_ENABLE;
  hadc3.Init.EOCSelection = ADC_EOC_SINGLE_CONV;
  hadc3.Init.LowPowerAutoWait = DISABLE;
  hadc3.Init.ContinuousConvMode = DISABLE;
  hadc3.Init.NbrOfConversion = 2;
  hadc3.Init.DiscontinuousConvMode = DISABLE;
  hadc3.Init.ExternalTrigConv = ADC_EXTERNALTRIG_T20_TRGO;
  hadc3.Init.ExternalTrigConvEdge = ADC_EXTERNALTRIGCONVEDGE_RISING;
  hadc3.Init.DMAContinuousRequests = ENABLE;
  hadc3.Init.Overrun = ADC_OVR_DATA_PRESERVED;
  hadc3.Init.OversamplingMode = DISABLE;
  if (HAL_ADC_Init(&hadc3) != HAL_OK)
  {
    Error_Handler();
  }

  /** Configure Regular Channel
  */
  sConfig.Channel = ADC_CHANNEL_1;
  sConfig.Rank = ADC_REGULAR_RANK_1;
  sConfig.SamplingTime = ADC_SAMPLETIME_92CYCLES_5;
  sConfig.SingleDiff = ADC_SINGLE_ENDED;
  sConfig.OffsetNumber = ADC_OFFSET_NONE;
  sConfig.Offset = 0;
  if (HAL_ADC_ConfigChannel(&hadc3, &sConfig) != HAL_OK)
  {
    Error_Handler();
  }

  /** Configure Regular Channel
  */
  sConfig.Channel = ADC_CHANNEL_2;
  sConfig.Rank = ADC_REGULAR_RANK_2;
  if (HAL_ADC_ConfigChannel(&hadc3, &sConfig) != HAL_OK)
  {
    Error_Handler();
  }

}

static void MX_DAC1_Init(void)
{

  DAC_ChannelConfTypeDef sConfig = {0};

  /** DAC Initialization
  */
  hdac1.Instance = DAC1;
  if (HAL_DAC_Init(&hdac1) != HAL_OK)
  {
    Error_Handler();
  }

  /** DAC channel OUT1 config
  */
  sConfig.DAC_HighFrequency = DAC_HIGH_FREQUENCY_INTERFACE_MODE_AUTOMATIC;
  sConfig.DAC_DMADoubleDataMode = DISABLE;
  sConfig.DAC_SignedFormat = DISABLE;
  sConfig.DAC_SampleAndHold = DAC_SAMPLEANDHOLD_DISABLE;
  sConfig.DAC_Trigger = DAC_TRIGGER_T6_TRGO;
  sConfig.DAC_Trigger2 = DAC_TRIGGER_NONE;
  sConfig.DAC_OutputBuffer = DAC_OUTPUTBUFFER_ENABLE;
  sConfig.DAC_ConnectOnChipPeripheral = DAC_CHIPCONNECT_EXTERNAL;
  sConfig.DAC_UserTrimming = DAC_TRIMMING_FACTORY;
  if (HAL_DAC_ConfigChannel(&hdac1, &sConfig, DAC_CHANNEL_1) != HAL_OK)
  {
    Error_Handler();
  }

  /** DAC channel OUT2 config
  */
  sConfig.DAC_Trigger = DAC_TRIGGER_T7_TRGO;
  if (HAL_DAC_ConfigChannel(&hdac1, &sConfig, DAC_CHANNEL_2) != HAL_OK)
  {
    Error_Handler();
  }

}

static void MX_FMAC_Init(void)
{

  hfmac.Instance = FMAC;
  if (HAL_FMAC_Init(&hfmac) != HAL_OK)
  {
    Error_Handler();
  }

}

static void MX_I2C1_Init(void)
{

  hi2c1.Instance = I2C1;
  hi2c1.Init.Timing = 0x10707DBC;
  hi2c1.Init.OwnAddress1 = 0;
  hi2c1.Init.AddressingMode = I2C_ADDRESSINGMODE_7BIT;
  hi2c1.Init.DualAddressMode = I2C_DUALADDRESS_DISABLE;
  hi2c1.Init.OwnAddress2 = 0;
  hi2c1.Init.OwnAddress2Masks = I2C_OA2_NOMASK;
  hi2c1.Init.GeneralCallMode = I2C_GENERALCALL_DISABLE;
  hi2c1.Init.NoStretchMode = I2C_NOSTRETCH_DISABLE;
  if (HAL_I2C_Init(&hi2c1) != HAL_OK)
  {
    Error_Handler();
  }

  /** Configure Analogue filter
  */
  if (HAL_I2CEx_ConfigAnalogFilter(&hi2c1, I2C_ANALOGFILTER_ENABLE) != HAL_OK)
  {
    Error_Handler();
  }

  /** Configure Digital filter
  */
  if (HAL_I2CEx_ConfigDigitalFilter(&hi2c1, 0) != HAL_OK)
  {
    Error_Handler();
  }

}

static void MX_I2C2_Init(void)
{

  hi2c2.Instance = I2C2;
  hi2c2.Init.Timing = 0x10707DBC;
  hi2c2.Init.OwnAddress1 = 0;
  hi2c2.Init.AddressingMode = I2C_ADDRESSINGMODE_7BIT;
  hi2c2.Init.DualAddressMode = I2C_DUALADDRESS_DISABLE;
  hi2c2.Init.OwnAddress2 = 0;
  hi2c2.Init.OwnAddress2Masks = I2C_OA2_NOMASK;
  hi2c2.Init.GeneralCallMode = I2C_GENERALCALL_DISABLE;
  hi2c2.Init.NoStretchMode = I2C_NOSTRETCH_DISABLE;
  if (HAL_I2C_Init(&hi2c2) != HAL_OK)
  {
    Error_Handler();
  }

  /** Configure Analogue filter
  */
  if (HAL_I2CEx_ConfigAnalogFilter(&hi2c2, I2C_ANALOGFILTER_ENABLE) != HAL_OK)
  {
    Error_Handler();
  }

  /** Configure Digital filter
  */
  if (HAL_I2CEx_ConfigDigitalFilter(&hi2c2, 0) != HAL_OK)
  {
    Error_Handler();
  }

}

static void MX_I2C3_Init(void)
{

  hi2c3.Instance = I2C3;
  hi2c3.Init.Timing = 0x10707DBC;
  hi2c3.Init.OwnAddress1 = 0;
  hi2c3.Init.AddressingMode = I2C_ADDRESSINGMODE_7BIT;
  hi2c3.Init.DualAddressMode = I2C_DUALADDRESS_DISABLE;
  hi2c3.Init.OwnAddress2 = 0;
  hi2c3.Init.OwnAddress2Masks = I2C_OA2_NOMASK;
  hi2c3.Init.GeneralCallMode = I2C_GENERALCALL_DISABLE;
  hi2c3.Init.NoStretchMode = I2C_NOSTRETCH_DISABLE;
  if (HAL_I2C_Init(&hi2c3) != HAL_OK)
  {
    Error_Handler();
  }

  /** Configure Analogue filter
  */
  if (HAL_I2CEx_ConfigAnalogFilter(&hi2c3, I2C_ANALOGFILTER_ENABLE) != HAL_OK)
  {
    Error_Handler();
  }

  /** Configure Digital filter
  */
  if (HAL_I2CEx_ConfigDigitalFilter(&hi2c3, 0) != HAL_OK)
  {
    Error_Handler();
  }

}

static void MX_TIM6_Init(void)
{

  TIM_MasterConfigTypeDef sMasterConfig = {0};

  htim6.Instance = TIM6;
  htim6.Init.Prescaler = 8-1;
  htim6.Init.CounterMode = TIM_COUNTERMODE_UP;
  htim6.Init.Period = 7;
  htim6.Init.AutoReloadPreload = TIM_AUTORELOAD_PRELOAD_DISABLE;
  if (HAL_TIM_Base_Init(&htim6) != HAL_OK)
  {
    Error_Handler();
  }
  sMasterConfig.MasterOutputTrigger = TIM_TRGO_UPDATE;
  sMasterConfig.MasterSlaveMode = TIM_MASTERSLAVEMODE_DISABLE;
  if (HAL_TIMEx_MasterConfigSynchronization(&htim6, &sMasterConfig) != HAL_OK)
  {
    Error_Handler();
  }

}

static void MX_TIM7_Init(void)
{

  TIM_MasterConfigTypeDef sMasterConfig = {0};

  htim7.Instance = TIM7;
  htim7.Init.Prescaler = 8-1;
  htim7.Init.CounterMode = TIM_COUNTERMODE_UP;
  htim7.Init.Period = 7;
  htim7.Init.AutoReloadPreload = TIM_AUTORELOAD_PRELOAD_DISABLE;
  if (HAL_TIM_Base_Init(&htim7) != HAL_OK)
  {
    Error_Handler();
  }
  sMasterConfig.MasterOutputTrigger = TIM_TRGO_UPDATE;
  sMasterConfig.MasterSlaveMode = TIM_MASTERSLAVEMODE_DISABLE;
  if (HAL_TIMEx_MasterConfigSynchronization(&htim7, &sMasterConfig) != HAL_OK)
  {
    Error_Handler();
  }

}

static void MX_TIM20_Init(void)
{

  TIM_SlaveConfigTypeDef sSlaveConfig = {0};
  TIM_MasterConfigTypeDef sMasterConfig = {0};

  htim20.Instance = TIM20;
  htim20.Init.Prescaler = 8-1;
  htim20.Init.CounterMode = TIM_COUNTERMODE_UP;
  htim20.Init.Period = 7;
  htim20.Init.ClockDivision = TIM_CLOCKDIVISION_DIV1;
  htim20.Init.RepetitionCounter = 0;
  htim20.Init.AutoReloadPreload = TIM_AUTORELOAD_PRELOAD_DISABLE;
  if (HAL_TIM_Base_Init(&htim20) != HAL_OK)
  {
    Error_Handler();
  }
  sSlaveConfig.SlaveMode = TIM_SLAVEMODE_DISABLE;
  sSlaveConfig.InputTrigger = TIM_TS_ITR0;
  if (HAL_TIM_SlaveConfigSynchro(&htim20, &sSlaveConfig) != HAL_OK)
  {
    Error_Handler();
  }
  sMasterConfig.MasterOutputTrigger = TIM_TRGO_UPDATE;
  sMasterConfig.MasterOutputTrigger2 = TIM_TRGO2_RESET;
  sMasterConfig.MasterSlaveMode = TIM_MASTERSLAVEMODE_DISABLE;
  if (HAL_TIMEx_MasterConfigSynchronization(&htim20, &sMasterConfig) != HAL_OK)
  {
    Error_Handler();
  }

}

static void MX_USART1_UART_Init(void)
{

  huart1.Instance = USART1;
  huart1.Init.BaudRate = 115200;
  huart1.Init.WordLength = UART_WORDLENGTH_8B;
  huart1.Init.StopBits = UART_STOPBITS_1;
  huart1.Init.Parity = UART_PARITY_NONE;
  huart1.Init.Mode = UART_MODE_TX_RX;
  huart1.Init.HwFlowCtl = UART_HWCONTROL_NONE;
  huart1.Init.OverSampling = UART_OVERSAMPLING_16;
  huart1.Init.OneBitSampling = UART_ONE_BIT_SAMPLE_DISABLE;
  huart1.Init.ClockPrescaler = UART_PRESCALER_DIV1;
  huart1.AdvancedInit.AdvFeatureInit = UART_ADVFEATURE_NO_INIT;
  if (HAL_UART_Init(&huart1) != HAL_OK)
  {
    Error_Handler();
  }
  if (HAL_UARTEx_SetTxFifoThreshold(&huart1, UART_TXFIFO_THRESHOLD_1_8) != HAL_OK)
  {
    Error_Handler();
  }
  if (HAL_UARTEx_SetRxFifoThreshold(&huart1, UART_RXFIFO_THRESHOLD_1_8) != HAL_OK)
  {
    Error_Handler();
  }
  if (HAL_UARTEx_DisableFifoMode(&huart1) != HAL_OK)
  {
    Error_Handler();
  }

}

static void MX_USART2_UART_Init(void)
{

  huart2.Instance = USART2;
  huart2.Init.BaudRate = 115200;
  huart2.Init.WordLength = UART_WORDLENGTH_8B;
  huart2.Init.StopBits = UART_STOPBITS_1;
  huart2.Init.Parity = UART_PARITY_NONE;
  huart2.Init.Mode = UART_MODE_TX_RX;
  huart2.Init.HwFlowCtl = UART_HWCONTROL_NONE;
  huart2.Init.OverSampling = UART_OVERSAMPLING_16;
  huart2.Init.OneBitSampling = UART_ONE_BIT_SAMPLE_DISABLE;
  huart2.Init.ClockPrescaler = UART_PRESCALER_DIV1;
  huart2.AdvancedInit.AdvFeatureInit = UART_ADVFEATURE_NO_INIT;
  if (HAL_UART_Init(&huart2) != HAL_OK)
  {
    Error_Handler();
  }
  if (HAL_UARTEx_SetTxFifoThreshold(&huart2, UART_TXFIFO_THRESHOLD_1_8) != HAL_OK)
  {
    Error_Handler();
  }
  if (HAL_UARTEx_SetRxFifoThreshold(&huart2, UART_RXFIFO_THRESHOLD_1_8) != HAL_OK)
  {
    Error_Handler();
  }
  if (HAL_UARTEx_DisableFifoMode(&huart2) != HAL_OK)
  {
    Error_Handler();
  }

}

static void MX_USART3_UART_Init(void)
{

  huart3.Instance = USART3;
  huart3.Init.BaudRate = 115200;
  huart3.Init.WordLength = UART_WORDLENGTH_8B;
  huart3.Init.StopBits = UART_STOPBITS_1;
  huart3.Init.Parity = UART_PARITY_NONE;
  huart3.Init.Mode = UART_MODE_TX_RX;
  huart3.Init.HwFlowCtl = UART_HWCONTROL_NONE;
  huart3.Init.OverSampling = UART_OVERSAMPLING_16;
  huart3.Init.OneBitSampling = UART_ONE_BIT_SAMPLE_DISABLE;
  huart3.Init.ClockPrescaler = UART_PRESCALER_DIV1;
  huart3.AdvancedInit.AdvFeatureInit = UART_ADVFEATURE_NO_INIT;
  if (HAL_UART_Init(&huart3) != HAL_OK)
  {
    Error_Handler();
  }
  if (HAL_UARTEx_SetTxFifoThreshold(&huart3, UART_TXFIFO_THRESHOLD_1_8) != HAL_OK)
  {
    Error_Handler();
  }
  if (HAL_UARTEx_SetRxFifoThreshold(&huart3, UART_RXFIFO_THRESHOLD_1_8) != HAL_OK)
  {
    Error_Handler();
  }
  if (HAL_UARTEx_DisableFifoMode(&huart3) != HAL_OK)
  {
    Error_Handler();
  }

}

static void MX_DMA_Init(void)
{

  /* DMA controller clock enable */
  __HAL_RCC_DMAMUX1_CLK_ENABLE();
  __HAL_RCC_DMA1_CLK_ENABLE();
  __HAL_RCC_DMA2_CLK_ENABLE();

  /* DMA interrupt init */
  /* DMA1_Channel1_IRQn interrupt configuration */
  HAL_NVIC_SetPriority(DMA1_Channel1_IRQn, 0, 0);
  HAL_NVIC_EnableIRQ(DMA1_Channel1_IRQn);
  /* DMA1_Channel2_IRQn interrupt configuration */
  HAL_NVIC_SetPriority(DMA1_Channel2_IRQn, 0, 0);
  HAL_NVIC_EnableIRQ(DMA1_Channel2_IRQn);
  /* DMA1_Channel3_IRQn interrupt configuration */
  HAL_NVIC_SetPriority(DMA1_Channel3_IRQn, 0, 0);
  HAL_NVIC_EnableIRQ(DMA1_Channel3_IRQn);
  /* DMA1_Channel4_IRQn interrupt configuration */
  HAL_NVIC_SetPriority(DMA1_Channel4_IRQn, 0, 0);
  HAL_NVIC_EnableIRQ(DMA1_Channel4_IRQn);
  /* DMA1_Channel5_IRQn interrupt configuration */
  HAL_NVIC_SetPriority(DMA1_Channel5_IRQn, 0, 0);
  HAL_NVIC_EnableIRQ(DMA1_Channel5_IRQn);
  /* DMA1_Channel6_IRQn interrupt configuration */
  HAL_NVIC_SetPriority(DMA1_Channel6_IRQn, 0, 0);
  HAL_NVIC_EnableIRQ(DMA1_Channel6_IRQn);
  /* DMA2_Channel1_IRQn interrupt configuration */
  HAL_NVIC_SetPriority(DMA2_Channel1_IRQn, 0, 0);
  HAL_NVIC_EnableIRQ(DMA2_Channel1_IRQn);
  /* DMA2_Channel4_IRQn interrupt configuration */
  HAL_NVIC_SetPriority(DMA2_Channel4_IRQn, 0, 0);
  HAL_NVIC_EnableIRQ(DMA2_Channel4_IRQn);
  /* DMA2_Channel5_IRQn interrupt configuration */
  HAL_NVIC_SetPriority(DMA2_Channel5_IRQn, 0, 0);
  HAL_NVIC_EnableIRQ(DMA2_Channel5_IRQn);
  /* DMA2_Channel6_IRQn interrupt configuration */
  HAL_NVIC_SetPriority(DMA2_Channel6_IRQn, 0, 0);
  HAL_NVIC_EnableIRQ(DMA2_Channel6_IRQn);
  /* DMA2_Channel7_IRQn interrupt configuration */
  HAL_NVIC_SetPriority(DMA2_Channel7_IRQn, 0, 0);
  HAL_NVIC_EnableIRQ(DMA2_Channel7_IRQn);

}

static void MX_GPIO_Init(void)
{
  GPIO_InitTypeDef GPIO_InitStruct = {0};

  /* GPIO Ports Clock Enable */
  __HAL_RCC_GPIOE_CLK_ENABLE();
  __HAL_RCC_GPIOF_CLK_ENABLE();
  __HAL_RCC_GPIOA_CLK_ENABLE();
  __HAL_RCC_GPIOC_CLK_ENABLE();
  __HAL_RCC_GPIOB_CLK_ENABLE();
  __HAL_RCC_GPIOD_CLK_ENABLE();

  /*Configure GPIO pin Output Level */
  HAL_GPIO_WritePin(GPIOE, GPIO_PIN_5, GPIO_PIN_RESET);

  /*Configure GPIO pin : GPIO_bgn_aqstn_Pin */
  GPIO_InitStruct.Pin = GPIO_bgn_aqstn_Pin;
  GPIO_InitStruct.Mode = GPIO_MODE_IT_RISING;
  GPIO_InitStruct.Pull = GPIO_PULLDOWN;
  HAL_GPIO_Init(GPIO_bgn_aqstn_GPIO_Port, &GPIO_InitStruct);

  /*Configure GPIO pin : PE5 */
  GPIO_InitStruct.Pin = GPIO_PIN_5;
  GPIO_InitStruct.Mode = GPIO_MODE_OUTPUT_PP;
  GPIO_InitStruct.Pull = GPIO_NOPULL;
  GPIO_InitStruct.Speed = GPIO_SPEED_FREQ_LOW;
  HAL_GPIO_Init(GPIOE, &GPIO_InitStruct);

}

/* USER CODE BEGIN 4 */
void EXT12_IRQHandler(void)
{

	  /* ADC1 is started using timer 6 triggered conversions */
	  HAL_StatusTypeDef HAL_TIM_Base_Start(TIM_HandleTypeDef *htim6);
      ADC_status = HAL_ADC_Start_DMA(&hadc1, ADC1_DMA_sort_ptr->ADC1_DMA_bfr, ADC_DMA_BUFFERSIZE);
	  HAL_ADC_ConvHalfCpltCallback(&hadc1);
	  HAL_ADC_ConvCpltCallback(&hadc1);

	  HAL_StatusTypeDef HAL_TIM_Base_Start(TIM_HandleTypeDef *htim7);
	  ADC_status = HAL_ADC_Start_DMA(&hadc2, ADC2_DMA_sort_ptr->ADC2_DMA_bfr, ADC_DMA_BUFFERSIZE);
	  HAL_ADC_ConvHalfCpltCallback(&hadc2);
	  HAL_ADC_ConvCpltCallback(&hadc2);

	  HAL_StatusTypeDef HAL_TIM_Base_Start(TIM_HandleTypeDef *htim20);
	  ADC_status = HAL_ADC_Start_DMA(&hadc3, ADC3_DMA_sort_ptr->ADC3_DMA_bfr, ADC_DMA_BUFFERSIZE);
	  HAL_ADC_ConvHalfCpltCallback(&hadc3);
	  HAL_ADC_ConvCpltCallback(&hadc3);

	/* Calculating the offset value and standard deviation for the base line signal for all the channels */
	if(Offset_1_Calculated==0)
	{
	  float32_t OffsetSum_1 = 0.0f;
	  for (uint8_t a=0; a< NOOFITERATIONS_BL; a++) // Calculates the mean and standard deviation for the baseline of the signal for the first n buffer fills where n= NOOFITERATIONS_BL
		{
			/* Collects samples to fill the buffer */
			update_ADC1_IN1_FO_biquad_filter();  // Filters channel 1 data
			MA_ADC1_IN1_Update(&MovingAverage_ADC1_IN1);  // Fill the buffer with ADC data

			/* Calculate the offset from the filled buffer */
			Offset_1 = ADC1_IN1_OffsetCalc(&OffsetCalc_ADC1_IN1);
			OffsetSum_1 += Offset_1;
		}

	  Offset_1 = OffsetSum_1 / NOOFITERATIONS_BL;
	  Offset_1_Calculated = 1; // Set the flag indicating offset has been calculated

	  SD_BL_1 = ADC1_IN1_SD_BL(&SD_BL_ADC1_IN1, Offset_1); // Calculated the standard deviation for the last buffer fill
	}

	if(Offset_2_Calculated==0)
	{
	  float32_t OffsetSum_2;
	  for (uint8_t a=0; a< NOOFITERATIONS_BL; a++)
		{

			update_ADC1_IN2_FO_biquad_filter();
			MA_ADC1_IN2_Update(&MovingAverage_ADC1_IN2);

			Offset_2 = ADC1_IN2_OffsetCalc(&OffsetCalc_ADC1_IN2);
			OffsetSum_2 += Offset_2;
		}

	  Offset_2 = OffsetSum_2 / NOOFITERATIONS_BL;
	  Offset_2_Calculated = 1;

	  SD_BL_2 = ADC1_IN2_SD_BL(&SD_BL_ADC1_IN2, Offset_2);
	}

	if(Offset_3_Calculated==0)
	{
	  float32_t OffsetSum_3;
	  for (uint8_t a=0; a< NOOFITERATIONS_BL; a++)
		{

			update_ADC2_IN3_FO_biquad_filter();
			MA_ADC2_IN3_Update(&MovingAverage_ADC2_IN3);

			Offset_3 = ADC2_IN3_OffsetCalc(&OffsetCalc_ADC2_IN3);
			OffsetSum_3 += Offset_3;
		}

	  Offset_3 = OffsetSum_3 / NOOFITERATIONS_BL;
	  Offset_3_Calculated = 1;

	  SD_BL_3 = ADC2_IN3_SD_BL(&SD_BL_ADC2_IN3, Offset_3);
	}

	if(Offset_4_Calculated==0)
	{
	  float32_t OffsetSum_4;
	  for (uint8_t a=0; a< NOOFITERATIONS_BL; a++)
		{

			update_ADC2_IN4_FO_biquad_filter();
			MA_ADC2_IN4_Update(&MovingAverage_ADC2_IN4);

			Offset_4 = ADC2_IN4_OffsetCalc(&OffsetCalc_ADC2_IN4);
			OffsetSum_4 += Offset_4;
		}

	  Offset_4 = OffsetSum_4 / NOOFITERATIONS_BL;
	  Offset_4_Calculated = 1;

	  SD_BL_4 = ADC2_IN4_SD_BL(&SD_BL_ADC2_IN4, Offset_4);
	}

	if(Offset_5_Calculated==0)
	{
	  float32_t OffsetSum_5;
	  for (uint8_t a=0; a< NOOFITERATIONS_BL; a++) // Calculates the mean and standard deviation for the baseline of the signal for the first n buffer fills where n= NOOFITERATIONS_BL
		{
			/* Collects samples to fill the buffer */
			update_ADC3_IN1_FO_biquad_filter();  // Notch filters channel 1 data
			MA_ADC3_IN1_Update(&MovingAverage_ADC3_IN1);  // Fill the buffer with ADC data

			/* Calculate the offset from the filled buffer */
			Offset_1 = ADC3_IN1_OffsetCalc(&OffsetCalc_ADC3_IN1);
			OffsetSum_5 += Offset_5;
		}

	  Offset_5 = OffsetSum_5 / NOOFITERATIONS_BL;
	  Offset_5_Calculated = 1; // Set the flag indicating offset has been calculated

	  SD_BL_5 = ADC3_IN1_SD_BL(&SD_BL_ADC3_IN1, Offset_5);
	}

	if(Offset_6_Calculated==0)
	{
	  float32_t OffsetSum_6;
	  for (uint8_t a=0; a< NOOFITERATIONS_BL; a++)
		{

			update_ADC3_IN2_FO_biquad_filter();
			MA_ADC3_IN2_Update(&MovingAverage_ADC3_IN2);

			Offset_6 = ADC3_IN2_OffsetCalc(&OffsetCalc_ADC3_IN2);
			OffsetSum_6 += Offset_6;
		}

	  Offset_6 = OffsetSum_6 / NOOFITERATIONS_BL;
	  Offset_6_Calculated = 1;

	  SD_BL_6 = ADC3_IN2_SD_BL(&SD_BL_ADC3_IN2, Offset_6);
	}

	HAL_GPIO_EXTI_IRQHandler(GPIO_PIN_2);  // Calls the HAL's callback function
}

void HAL_GPIO_EXTI_Callback(uint16_t GPIO_Pin) // Callback function (Called by HAL_GPIO_EXTI_IRQHandler (above))
{
	if (GPIO_Pin == GPIO_PIN_2)
	{
		// Turn the LED connected to PE5 on
        HAL_GPIO_WritePin(GPIOE, GPIO_PIN_5, GPIO_PIN_SET);

        // Delay for 2 seconds (2000 milliseconds)
        HAL_Delay(2000);

        // Turn the LED off
        HAL_GPIO_WritePin(GPIOE, GPIO_PIN_5, GPIO_PIN_RESET);
	}
}

void                    HAL_ADC_ConvHalfCpltCallback(ADC_HandleTypeDef *hadc)   // Fires when the upper half of the DMA buffer is filled
{
	 if (hadc->Instance == ADC1)
	   {
	        ADC1_DMA_sort_uhb(); // Handles the upper half of the DMA buffer

	        ADC1_DMA_sort_ptr->ADC1_DMA_mon=ADC1_DMA_sort_ptr->ADC1_DMA_bfr[ADC_DMA_QUATERBUFFERSIZE];  // Monitors one of the DMA buffer registers in the upper half of the buffer
	        ADC1_DMA_sort_ptr->ADC1_IN1_mon=ADC1_DMA_sort_ptr->ADC1_IN1_bfr[ADC_DMA_EIGHTHBUFFERSIZE];  // Monitors one of the IN1 data buffer registers in the upper half of the buffer
	        ADC1_DMA_sort_ptr->ADC1_IN2_mon=ADC1_DMA_sort_ptr->ADC1_IN2_bfr[ADC_DMA_EIGHTHBUFFERSIZE];  // Monitors one of the IN2 data buffer registers in the upper half of the buffer
	   }

	 if (hadc->Instance == ADC2)

	   {
		    ADC2_DMA_sort_uhb();

		    ADC2_DMA_sort_ptr->ADC2_DMA_mon=ADC2_DMA_sort_ptr->ADC2_DMA_bfr[ADC_DMA_QUATERBUFFERSIZE];
		    ADC2_DMA_sort_ptr->ADC2_IN3_mon=ADC2_DMA_sort_ptr->ADC2_IN3_bfr[ADC_DMA_EIGHTHBUFFERSIZE];
		    ADC2_DMA_sort_ptr->ADC2_IN4_mon=ADC2_DMA_sort_ptr->ADC2_IN4_bfr[ADC_DMA_EIGHTHBUFFERSIZE];
	   }

	 if (hadc->Instance == ADC3)

	   {
		    ADC3_DMA_sort_uhb();

		    ADC3_DMA_sort_ptr->ADC3_DMA_mon=ADC3_DMA_sort_ptr->ADC3_DMA_bfr[ADC_DMA_QUATERBUFFERSIZE];
		    ADC3_DMA_sort_ptr->ADC3_IN1_mon=ADC3_DMA_sort_ptr->ADC3_IN1_bfr[ADC_DMA_EIGHTHBUFFERSIZE];
		    ADC3_DMA_sort_ptr->ADC3_IN2_mon=ADC3_DMA_sort_ptr->ADC3_IN2_bfr[ADC_DMA_EIGHTHBUFFERSIZE];
	   }
};

void                    HAL_ADC_ConvCpltCallback(ADC_HandleTypeDef *hadc)  // Fires when the lower half of the DMA buffer is filled
{
	  if (hadc->Instance == ADC1)
		{
			ADC1_DMA_sort_lhb(); // Handles the lower half of the DMA buffer

			ADC1_DMA_sort_ptr->ADC1_DMA_mon=ADC1_DMA_sort_ptr->ADC1_DMA_bfr[ADC_DMA_HALFBUFFERSIZE + ADC_DMA_QUATERBUFFERSIZE]; // Monitors one of the DMA buffer registers in the lower half of the buffer
			ADC1_DMA_sort_ptr->ADC1_IN1_mon=ADC1_DMA_sort_ptr->ADC1_IN1_bfr[ADC_DMA_QUATERBUFFERSIZE + ADC_DMA_EIGHTHBUFFERSIZE];  // Monitors one of the IN1 data buffer registers in the lower half of the buffer
			ADC1_DMA_sort_ptr->ADC1_IN2_mon=ADC1_DMA_sort_ptr->ADC1_IN2_bfr[ADC_DMA_QUATERBUFFERSIZE + ADC_DMA_EIGHTHBUFFERSIZE];  // Monitors one of the IN2 data buffer registers in the lower half of the buffer

			Buffer_ADC1_Ready = 1; // Sets a flag to zero after the channel specific buffers have been filled
		}

	  if (hadc->Instance == ADC2)

		{
			 ADC2_DMA_sort_lhb();

			 ADC2_DMA_sort_ptr->ADC2_DMA_mon=ADC2_DMA_sort_ptr->ADC2_DMA_bfr[ADC_DMA_HALFBUFFERSIZE + ADC_DMA_QUATERBUFFERSIZE];
			 ADC2_DMA_sort_ptr->ADC2_IN3_mon=ADC2_DMA_sort_ptr->ADC2_IN3_bfr[ADC_DMA_QUATERBUFFERSIZE + ADC_DMA_EIGHTHBUFFERSIZE];
			 ADC2_DMA_sort_ptr->ADC2_IN4_mon=ADC2_DMA_sort_ptr->ADC2_IN4_bfr[ADC_DMA_QUATERBUFFERSIZE + ADC_DMA_EIGHTHBUFFERSIZE];

			 Buffer_ADC2_Ready = 1;
		}

	   if (hadc->Instance == ADC3)

		{
		     ADC3_DMA_sort_lhb();

			 ADC3_DMA_sort_ptr->ADC3_DMA_mon=ADC3_DMA_sort_ptr->ADC3_DMA_bfr[ADC_DMA_HALFBUFFERSIZE + ADC_DMA_QUATERBUFFERSIZE];
			 ADC3_DMA_sort_ptr->ADC3_IN1_mon=ADC3_DMA_sort_ptr->ADC3_IN1_bfr[ADC_DMA_QUATERBUFFERSIZE + ADC_DMA_EIGHTHBUFFERSIZE];
			 ADC3_DMA_sort_ptr->ADC3_IN2_mon=ADC3_DMA_sort_ptr->ADC3_IN2_bfr[ADC_DMA_QUATERBUFFERSIZE + ADC_DMA_EIGHTHBUFFERSIZE];

			 Buffer_ADC3_Ready = 1;
		}

};

/* USER CODE END 4 */

void Error_Handler(void)
{
  __disable_irq();
  while (1)
  {
  }
}
